# STM32H523xx register map
File version: 1.0
Registers are 32-bit, read-write, reset 0x0 unless marked. A register's access mark holds for its fields unless they carry their own. Offsets are from the block's base; [hi:lo] are bit positions; {n}, {i} and the like mark numbered series.

## EXTI — Asynch Interrupt/Event Controller (EXTI)
Base 0x44022000
Same registers: EXTI_S 0x54022000
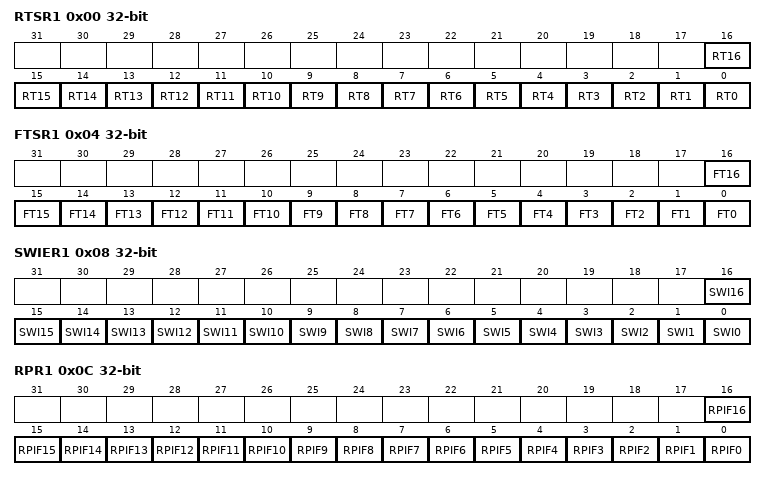
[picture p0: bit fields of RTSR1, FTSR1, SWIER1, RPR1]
0x00 RTSR1 — EXTI Rising Trigger Selection Register 1
  [n] RT{n} (n=0..16) — Rising trigger configuration for input line {n}
0x04 FTSR1 — EXTI Falling Trigger Selection Register 1
  [n] FT{n} (n=0..16) — Falling trigger configuration for input line {n}
0x08 SWIER1 — EXTI Software Interrupt event Register 1
  [n] SWI{n} (n=0..16) — Software Interrupt on line {n}
0x0C RPR1 — EXTI Rising Pending Register 1
  [n] RPIF{n} (n=0..16) — Rising Pending Interrupt Flag on line {n}
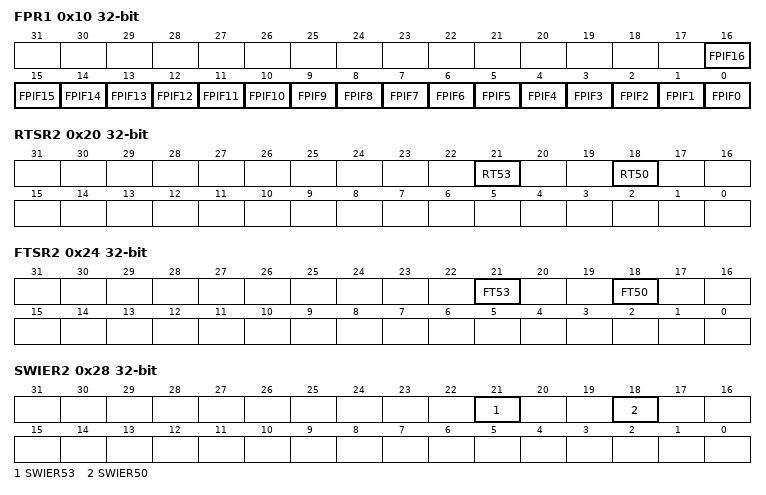
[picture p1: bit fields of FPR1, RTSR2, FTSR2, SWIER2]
0x10 FPR1 — EXTI Falling Pending Register 1
  [n] FPIF{n} (n=0..16) — Falling Pending Interrupt Flag on line {n}
0x14 SECCFGR1 — EXTI Security Configuration Register 1
0x18 PRIVCFGR1 — EXTI Privilege Configuration Register 1
0x20 RTSR2 — EXTI Rising Trigger Selection Register 2
  [21] RT53 — Rising trigger event configuration bit of line 53
  [18] RT50 — Rising trigger event configuration bit of line 50
0x24 FTSR2 — EXTI Falling Trigger Selection Register 2
  [21] FT53 — Falling trigger event configuration bit of line 53
  [18] FT50 — Falling trigger event configuration bit of line 50
0x28 SWIER2 — EXTI Software Interrupt event Register 2
  [21] SWIER53 — Software Interrupt on line 53
  [18] SWIER50 — Software Interrupt on line 50
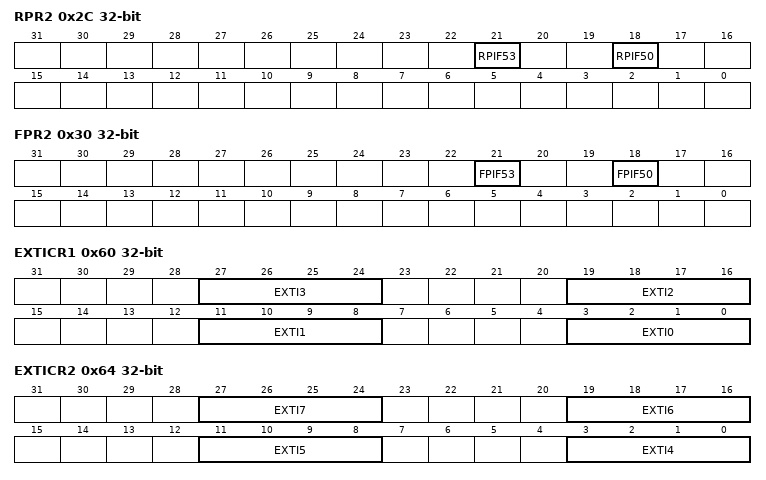
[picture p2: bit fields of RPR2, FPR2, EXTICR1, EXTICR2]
0x2C RPR2 — EXTI Rising Pending Register 2
  [21] RPIF53 — Rising pending edge configuration bit of line 53
  [18] RPIF50 — Rising pending edge configuration bit of line 50
0x30 FPR2 — EXTI Falling Pending Register 2
  [21] FPIF53 — Rising falling edge configuration bit of line 53
  [18] FPIF50 — Rising falling edge configuration bit of line 50
0x34 SECCFGR2 — EXTI Security Configuration Register 2
0x38 PRIVCFGR2 — EXTI Privilege Configuration Register 2
0x60 EXTICR1 — EXIT External Interrupt Configuration Register, 0x60 -- 0x6C
  [8n+3:8n] EXTI{n} (n=0..3) — EXTI {n} configuration
0x64 EXTICR2 — EXIT External Interrupt Configuration Register, 0x60 -- 0x6C
  [8n-29:8n-32] EXTI{n} (n=4..7) — EXTI {n} configuration
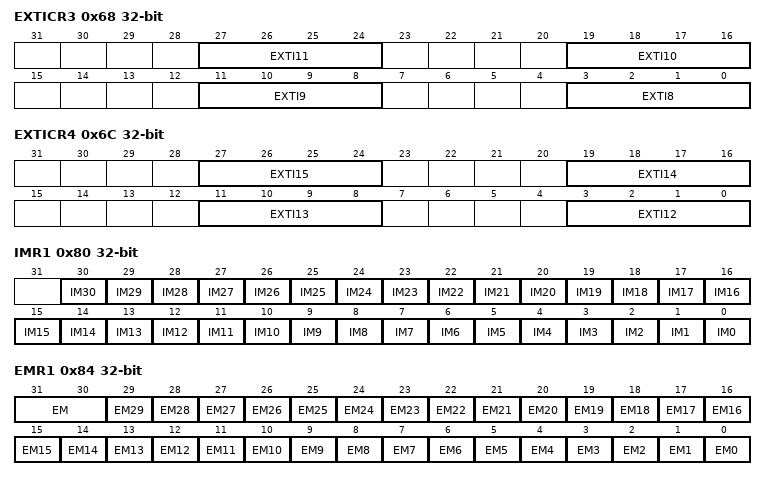
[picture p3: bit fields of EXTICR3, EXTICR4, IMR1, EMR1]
0x68 EXTICR3 — EXIT External Interrupt Configuration Register, 0x60 -- 0x6C
  [8n-61:8n-64] EXTI{n} (n=8..11) — EXTI {n} configuration
0x6C EXTICR4 — EXIT External Interrupt Configuration Register, 0x60 -- 0x6C
  [8n-93:8n-96] EXTI{n} (n=12..15) — EXTI {n} configuration
0x70 LOCKR — EXTI Lock Register
  [0] LOCK — Lock Mask
0x80 IMR1 — EXTI Interrupt Mask Register 1
  [n] IM{n} (n=0..30) — Interrupt Mask on line {n}
0x84 EMR1 — EXTI Event Mask Register 1
  [31:30] EM — Event Mask
  [n] EM{n} (n=0..29) — Event Mask on line {n}
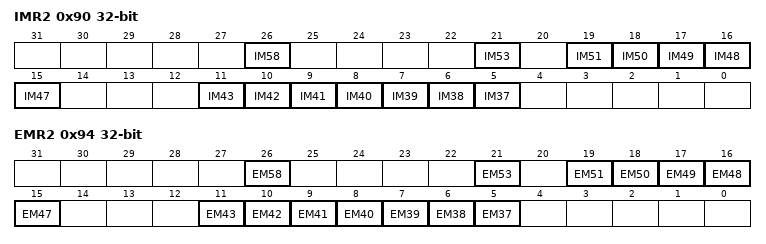
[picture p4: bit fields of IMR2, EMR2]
0x90 IMR2 — EXTI Interrupt Mask Register 2
  [26] IM58 — Interrupt Mask on line 58
  [21] IM53 — Interrupt Mask on line 53
  [n-32] IM{n} (n=47..51) — Interrupt Mask on line {n}
  [n-32] IM{n} (n=37..43) — Interrupt Mask on line {n}
0x94 EMR2 — EXTI Event Mask Register 2
  [26] EM58 — Event Mask on line 58
  [21] EM53 — Event Mask on line 53
  [n-32] EM{n} (n=47..51) — Event Mask on line {n}
  [n-32] EM{n} (n=37..43) — Event Mask on line {n}

## DBGMCU — Debug MCU
Base 0x44024000
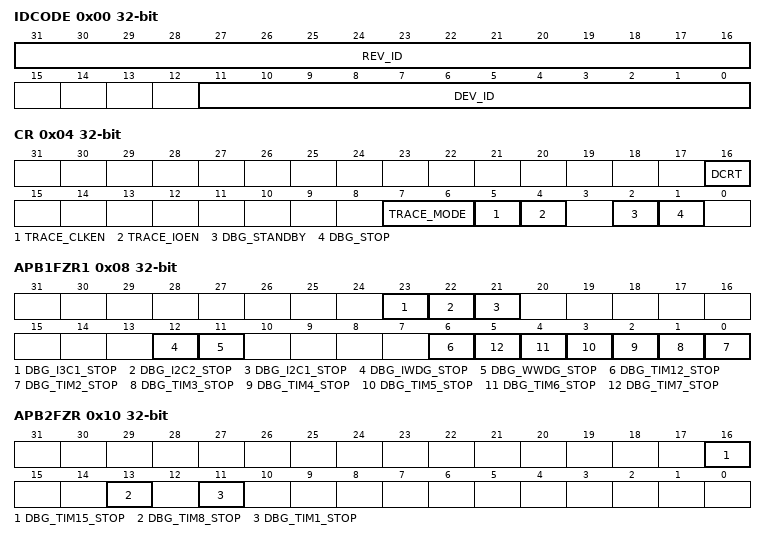
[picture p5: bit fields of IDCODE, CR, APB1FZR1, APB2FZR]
0x00 IDCODE — MCU device ID code
  [31:16] REV_ID, [11:0] DEV_ID
0x04 CR — Debug MCU configuration register
  [16] DCRT, [7:6] TRACE_MODE, [5] TRACE_CLKEN, [4] TRACE_IOEN, [2] DBG_STANDBY, [1] DBG_STOP
0x08 APB1FZR1 — Debug MCU APB1 freeze register 1
  [23] DBG_I3C1_STOP, [22] DBG_I2C2_STOP, [21] DBG_I2C1_STOP, [12] DBG_IWDG_STOP, [11] DBG_WWDG_STOP, [6] DBG_TIM12_STOP, [n-2] DBG_TIM{n}_STOP (n=2..7)
0x0C APB1FZR2 — Debug MCU APB1 freeze register 2
  [5] DBG_LPTIM2_STOP
0x10 APB2FZR — Debug MCU APB2 freeze register
  [16] DBG_TIM15_STOP, [13] DBG_TIM8_STOP, [11] DBG_TIM1_STOP
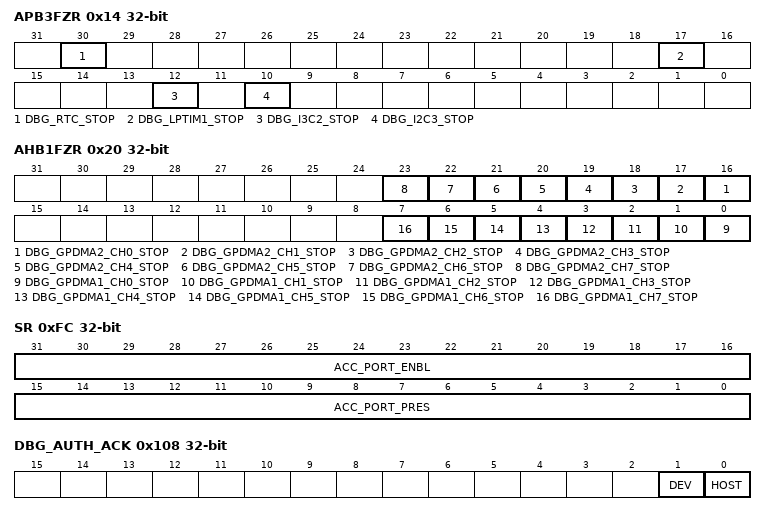
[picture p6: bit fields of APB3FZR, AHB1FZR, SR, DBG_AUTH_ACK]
0x14 APB3FZR — Debug MCU APB3 freeze register
  [30] DBG_RTC_STOP, [17] DBG_LPTIM1_STOP, [12] DBG_I3C2_STOP, [10] DBG_I2C3_STOP
0x20 AHB1FZR — Debug MCU AHB1 freeze register
  [n+16] DBG_GPDMA2_CH{n}_STOP (n=0..7), [n] DBG_GPDMA1_CH{n}_STOP (n=0..7)
0xFC SR — Debug MCU SR register
  [31:16] ACC_PORT_ENBL, [15:0] ACC_PORT_PRES
0x100 DBG_AUTH_HOST — Debug DBG_AUTH_HOST register
0x104 DBG_AUTH_DEV — Debug DBG_AUTH_DEV register
0x108 DBG_AUTH_ACK — Debug DBG_AUTH_ACK register
  [1] DEV, [0] HOST
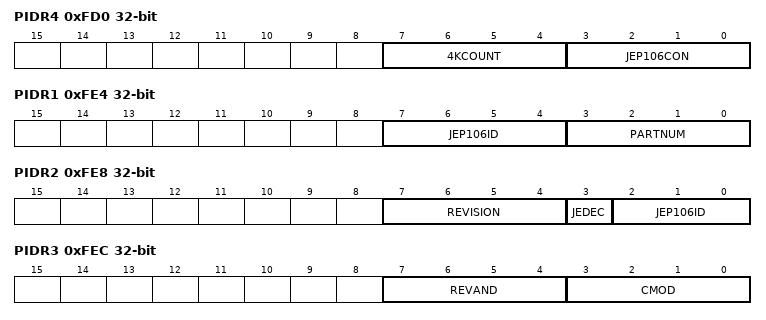
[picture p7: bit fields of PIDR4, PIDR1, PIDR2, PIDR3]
0xFD0 PIDR4 — Debug MCU Peripheral ID register 4
  [7:4] 4KCOUNT, [3:0] JEP106CON
{0xFC0+4i} PIDR{i} (i=5..7) — Debug MCU Peripheral ID register {i}
0xFE0 PIDR0 — Debug MCU Peripheral ID register 0
  [7:0] PARTNUM
0xFE4 PIDR1 — Debug MCU Peripheral ID register 1
  [7:4] JEP106ID, [3:0] PARTNUM
0xFE8 PIDR2 — Debug MCU Peripheral ID register 2
  [7:4] REVISION, [3] JEDEC, [2:0] JEP106ID
0xFEC PIDR3 — Debug MCU Peripheral ID register 3
  [7:4] REVAND, [3:0] CMOD
0xFF0 CIDR0 — Debug MCU Component ID register 0
  [7:0] PREAMBLE
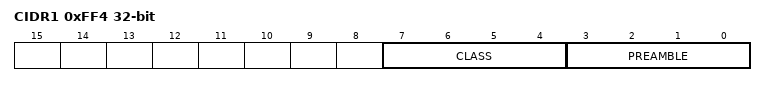
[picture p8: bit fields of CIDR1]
0xFF4 CIDR1 — Debug MCU Component ID register 1
  [7:4] CLASS, [3:0] PREAMBLE
0xFF8 CIDR2 — Debug MCU Component ID register 2
  [7:0] PREAMBLE
0xFFC CIDR3 — Debug MCU Component ID register 3
  [7:0] PREAMBLE
